AUTOSAR XML (schema 00050)
package /ComponentTypes
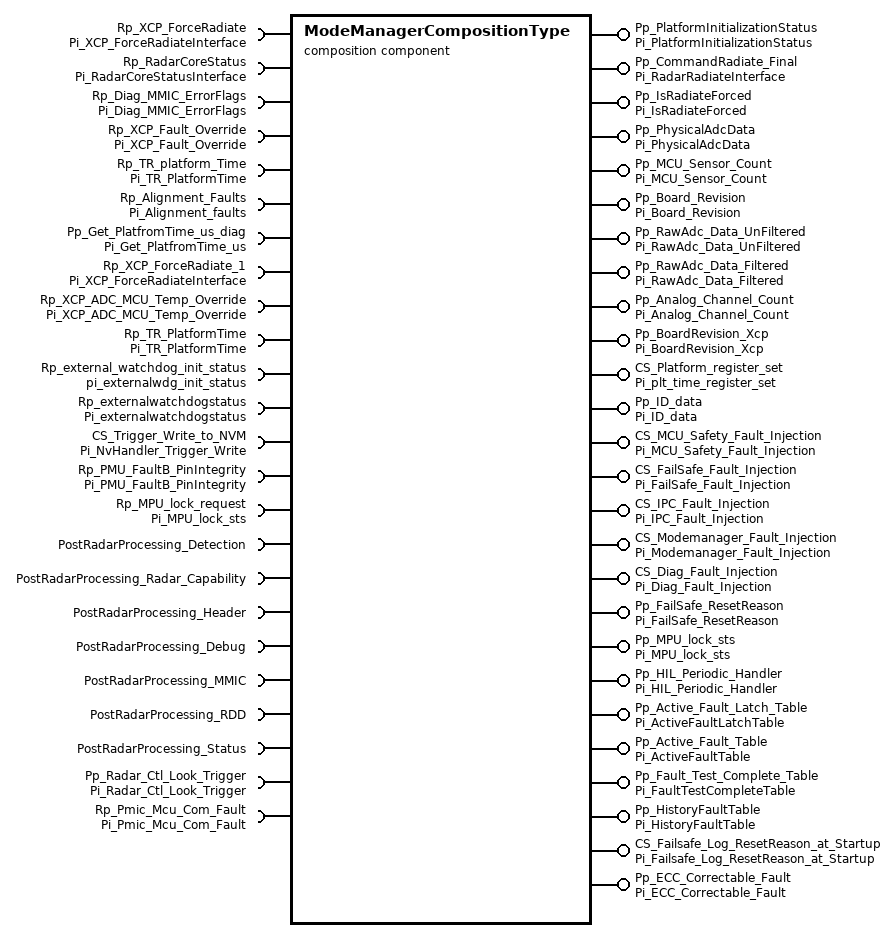
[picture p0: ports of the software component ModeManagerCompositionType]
  composition sw component type ModeManagerCompositionType
    provide port Pp_PlatformInitializationStatus: nonqueued-sender-com-spec{data-element=De_MCU_InitializationStatus, init-value=constant-reference=C_MCU_initlaisation_NOTCompleted_T}, provided-interface=Pi_PlatformInitializationStatus
    require port Rp_XCP_ForceRadiate: nonqueued-receiver-com-spec{data-element=De_XCPForceRadiate, filter=data-filter-type=ALWAYS, init-value=constant-reference=C_Force_Radiate_Init_T}, required-interface=Pi_XCP_ForceRadiateInterface
    provide port Pp_CommandRadiate_Final: nonqueued-sender-com-spec{data-element=De_CommandRadiate_Final, init-value=constant-reference=C_Command_Radiate_Final_T}, provided-interface=Pi_RadarRadiateInterface
    provide port Pp_IsRadiateForced: nonqueued-sender-com-spec{data-element=De_IsRadiateForced, init-value=constant-reference=C_IsRadiateForced_T}, provided-interface=Pi_IsRadiateForced
    8 x require port:
      Rp_RadarCoreStatus: nonqueued-receiver-com-spec{data-element=De_RadarCoreStatus, filter=data-filter-type=ALWAYS, init-value=constant-reference=C_RadarCoreStatus_T}, required-interface=Pi_RadarCoreStatusInterface
      Rp_Diag_MMIC_ErrorFlags: nonqueued-receiver-com-spec{data-element=De_MMIC_ErrorFlags, filter=data-filter-type=ALWAYS, init-value=constant-reference=C_MMIC_ErrorFlags}, required-interface=Pi_Diag_MMIC_ErrorFlags
      Rp_XCP_Fault_Override: nonqueued-receiver-com-spec{data-element=De_XCP_Fault_Override, filter=data-filter-type=ALWAYS, init-value=constant-reference=C_XCP_Fault_Override}, required-interface=Pi_XCP_Fault_Override
      Rp_TR_platform_Time: nonqueued-receiver-com-spec{data-element=De_PlatformTime, filter=data-filter-type=ALWAYS, init-value=85}, required-interface=Pi_TR_PlatformTime
      Rp_Alignment_Faults: nonqueued-receiver-com-spec{data-element=De_Alignment_Faults, filter=data-filter-type=ALWAYS, init-value=constant-reference=C_Alignment_faults}, required-interface=Pi_Alignment_faults
      Pp_Get_PlatfromTime_us_diag: client-com-spec=read, required-interface=Pi_Get_PlatfromTime_us
      Rp_XCP_ForceRadiate_1: nonqueued-receiver-com-spec{data-element=De_XCPForceRadiate, filter=data-filter-type=ALWAYS, init-value=constant-reference=C_Force_Radiate_Init_T}, required-interface=Pi_XCP_ForceRadiateInterface
      Rp_XCP_ADC_MCU_Temp_Override: nonqueued-receiver-com-spec{data-element=De_XCP_ADC_MCU_Temp_Override, filter=data-filter-type=ALWAYS, init-value=1}, required-interface=Pi_XCP_ADC_MCU_Temp_Override
    10 x provide port:
      Pp_PhysicalAdcData: nonqueued-sender-com-spec{data-element=De_PhysicalAdcData, init-value=constant-reference=C_AdcData_T}, provided-interface=Pi_PhysicalAdcData
      Pp_MCU_Sensor_Count: nonqueued-sender-com-spec{data-element=De_MCU_Sensor_Count, init-value=0}, provided-interface=Pi_MCU_Sensor_Count
      Pp_Board_Revision: nonqueued-sender-com-spec{data-element=De_Board_Revision, init-value=85}, provided-interface=Pi_Board_Revision
      Pp_RawAdc_Data_UnFiltered: nonqueued-sender-com-spec{data-element=RawAdcDataUnfiltered, init-value=constant-reference=C_RawAdcData_T}, provided-interface=Pi_RawAdc_Data_UnFiltered
      Pp_RawAdc_Data_Filtered: nonqueued-sender-com-spec{data-element=De_RawAdcData, init-value=constant-reference=C_RawAdcDataFilt_T}, provided-interface=Pi_RawAdc_Data_Filtered
      Pp_Analog_Channel_Count: nonqueued-sender-com-spec{data-element=De_Analog_Channel_Count, init-value=0}, provided-interface=Pi_Analog_Channel_Count
      Pp_BoardRevision_Xcp: nonqueued-sender-com-spec{data-element=De_BoardRevision_Xcp, init-value=0}, provided-interface=Pi_BoardRevision_Xcp
      CS_Platform_register_set: server-com-spec{operation=fault_type, queue-length=1}, provided-interface=Pi_plt_time_register_set
      Pp_ID_data: nonqueued-sender-com-spec{data-element=De_ID_data, init-value=constant-reference=C_ID_data}, provided-interface=Pi_ID_data
      CS_MCU_Safety_Fault_Injection: server-com-spec{operation=Read, queue-length=1}, provided-interface=Pi_MCU_Safety_Fault_Injection
    require port Rp_TR_PlatformTime: nonqueued-receiver-com-spec{data-element=De_PlatformTime, filter=data-filter-type=ALWAYS, init-value=85}, required-interface=Pi_TR_PlatformTime
    provide port CS_FailSafe_Fault_Injection: server-com-spec{operation=Read, queue-length=1}, provided-interface=Pi_FailSafe_Fault_Injection
    provide port CS_IPC_Fault_Injection: server-com-spec{operation=Read, queue-length=1}, provided-interface=Pi_IPC_Fault_Injection
    require port Rp_external_watchdog_init_status: nonqueued-receiver-com-spec{data-element=de_wdginit_status, filter=data-filter-type=ALWAYS, init-value=0}, required-interface=pi_externalwdg_init_status
    require port Rp_externalwatchdogstatus: nonqueued-receiver-com-spec{data-element=de_externalwatchdogstatus, filter=data-filter-type=ALWAYS, init-value=0}, required-interface=Pi_externalwatchdogstatus
    provide port CS_Modemanager_Fault_Injection: server-com-spec{operation=Read, queue-length=1}, provided-interface=Pi_Modemanager_Fault_Injection
    provide port CS_Diag_Fault_Injection: server-com-spec{operation=Read, queue-length=1}, provided-interface=Pi_Diag_Fault_Injection
    provide port Pp_FailSafe_ResetReason: nonqueued-sender-com-spec{data-element=De_FailSafe_ResetReason, init-value=constant-reference=C_FailSafe_ResetReason_T}, provided-interface=Pi_FailSafe_ResetReason
    require port CS_Trigger_Write_to_NVM: client-com-spec=NvHandler_Trigger_Write_To_NVM, required-interface=Pi_NvHandler_Trigger_Write
    require port Rp_PMU_FaultB_PinIntegrity: nonqueued-receiver-com-spec{data-element=De_PMU_FaultB_PinIntegrityStat, filter=data-filter-type=ALWAYS, init-value=0}, required-interface=Pi_PMU_FaultB_PinIntegrity
    provide port Pp_MPU_lock_sts: nonqueued-sender-com-spec{data-element=De_MPU_lock_sts, init-value=0}, provided-interface=Pi_MPU_lock_sts
    require port Rp_MPU_lock_request: nonqueued-receiver-com-spec{data-element=De_MPU_lock_sts, filter=data-filter-type=ALWAYS, init-value=0}, required-interface=Pi_MPU_lock_sts
    6 x provide port:
      Pp_HIL_Periodic_Handler: provided-interface=Pi_HIL_Periodic_Handler
      Pp_Active_Fault_Latch_Table: nonqueued-sender-com-spec{data-element=De_ActiveFaultLatchTable, init-value=constant-reference=C_Fault_T}, provided-interface=Pi_ActiveFaultLatchTable
      Pp_Active_Fault_Table: nonqueued-sender-com-spec{data-element=De_ActiveFaultTable, init-value=constant-reference=C_Fault_T}, provided-interface=Pi_ActiveFaultTable
      Pp_Fault_Test_Complete_Table: nonqueued-sender-com-spec{data-element=De_FaultTestCompleteTable, init-value=constant-reference=C_Fault_T}, provided-interface=Pi_FaultTestCompleteTable
      Pp_HistoryFaultTable: nonqueued-sender-com-spec{data-element=De_HistoryFaultTable, init-value=constant-reference=C_Fault_T}, provided-interface=Pi_HistoryFaultTable
      CS_Failsafe_Log_ResetReason_at_Startup: provided-interface=Pi_Failsafe_Log_ResetReason_at_Startup
    8 x require port:
      PostRadarProcessing_Detection: client-com-spec=Populate_Detection_Stream, required-interface=PostRadarProcessing_Detection
      PostRadarProcessing_Radar_Capability: client-com-spec=Populate_Radar_Capability_Stream, required-interface=PostRadarProcessing_Radar_Capability
      PostRadarProcessing_Header: client-com-spec=Populate_Header_Stream, required-interface=PostRadarProcessing_Header
      PostRadarProcessing_Debug: client-com-spec=Populate_Debug_Stream, required-interface=PostRadarProcessing_Debug
      PostRadarProcessing_MMIC: client-com-spec=Populate_MMIC_Stream, required-interface=PostRadarProcessing_MMIC
      PostRadarProcessing_RDD: client-com-spec=Populate_RDD_Stream, required-interface=PostRadarProcessing_RDD
      PostRadarProcessing_Status: client-com-spec=Populate_Status_Stream, required-interface=PostRadarProcessing_Status
      Pp_Radar_Ctl_Look_Trigger: client-com-spec=Operation, required-interface=Pi_Radar_Ctl_Look_Trigger
    provide port Pp_ECC_Correctable_Fault: nonqueued-sender-com-spec{data-element=De_ECC_Correctable_Fault, init-value=fields=[aa_mem_sec:0, artie_mem_sec:0, csi2_sec:0, dsp_opif_sec:0, dsp_idma_sec:0, dsp_iram_sec_axis:0, dsp_dcache_sec:0, dsp_dram_sec:0, dsp_icache_sec:0, dsp_iram_sec:0, ra_cqmem_sec:0, ra_dpmem_sec:0, ra_estmem_sec:0, ra_idxmem_sec:0, ra_phmem_sec:0, ra_wcmem_sec:0, sp_axi_m_corr:0, sp_axi_s_corr:0, sysmem0_sec:0, sysmem1_sec:0, not_recorded:0]}, provided-interface=Pi_ECC_Correctable_Fault
    require port Rp_Pmic_Mcu_Com_Fault: nonqueued-receiver-com-spec{data-element=De_Pmic_Mcu_Com_Fault, filter=data-filter-type=ALWAYS, init-value=0}, required-interface=Pi_Pmic_Mcu_Com_Fault
    7 x component:
      SWC_CDD_IPC: type=SWC_CDD_IPC
      SWC_PLT_Appl_Diag: type=SWC_PLT_Appl_Diag
      SWC_PLT_Appl_FaultMgr: type=SWC_PLT_Appl_FaultMgr
      SWC_PLT_Appl_IoHwAb: type=SWC_PLT_Appl_IoHwAb
      SWC_PLT_Appl_ModeManager: type=SWC_PLT_Appl_ModeManager
      SWC_PLT_CDD_FailSafe: type=SWC_PLT_CDD_FailSafe
      SWC_PLT_CDD_MCU_Safety: type=SWC_PLT_CDD_MCU_Safety
    connect SWC_PLT_Appl_Diag.Pp_DTC_Status -> SWC_PLT_Appl_FaultMgr.Rp_DTC_Status
    connect SWC_PLT_Appl_Diag.Pp_MCU_Startup_Fault_Status -> SWC_PLT_Appl_FaultMgr.Rp_MCU_Startup_Fault_Status
    connect SWC_PLT_Appl_Diag.Pp_MicroTemp_Low_Deb_Reset -> SWC_PLT_Appl_FaultMgr.Rp_MicroTemp_Low_Deb_Reset
    connect SWC_PLT_Appl_Diag.Pp_Platform_Battery_Tst -> SWC_PLT_Appl_FaultMgr.Rp_Platform_Battery_Tst
    connect SWC_PLT_Appl_Diag.Pp_PltToFltMgr_Can_Bus_Off_Fault_Status -> SWC_PLT_Appl_FaultMgr.Rp_PltToFltMgr_Can_Bus_Off_Fault_Status
    connect SWC_PLT_Appl_Diag.Pp_PltToFltMgr_Can_Controller_Fault_Status -> SWC_PLT_Appl_FaultMgr.Rp_PltToFltMgr_Can_Controller_Fault_Status
    connect SWC_PLT_Appl_Diag.Pp_PltToFltMgr_Host_Micro_Diag -> SWC_PLT_Appl_FaultMgr.Rp_PltToFltMgr_Host_Micro_Diag
    connect SWC_PLT_Appl_Diag.Pp_PltToFltMgr_Micro_Temp_Fault_Status -> SWC_PLT_Appl_FaultMgr.Rp_PltToFltMgr_Micro_Temp_Fault_Status
    connect SWC_PLT_Appl_Diag.Pp_PltToFltMgr_Mirror_Ram_Int_Flt_Sts -> SWC_PLT_Appl_FaultMgr.Rp_PltToFltMgr_Mirror_Ram_Int_Flt_Sts
    connect SWC_PLT_Appl_Diag.Pp_PltToFltMgr_MMIC_A_MMIC_Diag -> SWC_PLT_Appl_FaultMgr.Rp_PltToFltMgr_MMIC_A_MMIC_Diag
    connect SWC_PLT_Appl_Diag.Pp_PltToFltMgr_MMIC_B_Diag -> SWC_PLT_Appl_FaultMgr.Rp_PltToFltMgr_MMIC_B_Diag
    connect SWC_PLT_Appl_Diag.Pp_Radar_Blockage_Flt_Sts -> SWC_PLT_Appl_FaultMgr.Rp_Radar_Blockage_Flt_Sts
    connect SWC_PLT_Appl_Diag.Pp_Radar_Interference_Flt_Sts -> SWC_PLT_Appl_FaultMgr.Rp_Radar_Interference_Flt_Sts
    connect SWC_PLT_Appl_Diag.Pp_Rdr_Hw_Tst -> SWC_PLT_Appl_FaultMgr.Rp_Rdr_Hw_Tst
    connect SWC_PLT_Appl_FaultMgr.Pp_RadarDiagRequestInterface -> SWC_PLT_Appl_ModeManager.Rp_RadarDiagRequest
    connect SWC_PLT_Appl_FaultMgr.Pp_ModeManagerTestResultInterface -> SWC_PLT_Appl_ModeManager.Rp_TR_ModeManager
    connect SWC_PLT_Appl_IoHwAb.CS_ThermMonTemp -> SWC_PLT_Appl_Diag.CS_ThermMonTemp
    connect SWC_PLT_Appl_ModeManager.Pp_OperationMode_System -> SWC_PLT_Appl_Diag.Rp_Operation_Mode_System
    connect SWC_PLT_CDD_MCU_Safety.Pp_PlatformInitializationStatus -> SWC_PLT_Appl_Diag.Rp_PlatformInitializationStatus
    connect SWC_PLT_CDD_MCU_Safety.Pp_TR_initMCU_Fail -> SWC_PLT_Appl_Diag.Rp_TR_initMCU_Fail
    connect SWC_PLT_CDD_MCU_Safety.Pp_PlatformInitializationStatus -> SWC_PLT_Appl_ModeManager.Rp_InitializationStatus
    delegate SWC_PLT_Appl_ModeManager.Pp_CommandRadiate_Final <-> outer port Pp_CommandRadiate_Final
    delegate SWC_PLT_Appl_ModeManager.Pp_IsRadiateForced <-> outer port Pp_IsRadiateForced
    delegate SWC_PLT_Appl_ModeManager.Rp_RadarCoreStatus <-> outer port Rp_RadarCoreStatus
    delegate SWC_PLT_Appl_Diag.Rp_Diag_MMIC_ErrorFlags <-> outer port Rp_Diag_MMIC_ErrorFlags
    connect SWC_PLT_Appl_Diag.Pp_Alignment_Flt_Sts -> SWC_PLT_Appl_FaultMgr.Rp_Alignment_Flt_Sts
    connect SWC_PLT_Appl_Diag.Pp_IPC_Faults_sts -> SWC_PLT_Appl_FaultMgr.Rp_IPC_Faults_sts
    connect SWC_PLT_Appl_Diag.Pp_PltToFltMgr_InterProcessor_Commn -> SWC_PLT_Appl_FaultMgr.Rp_PltToFltMgr_InterProcessor_Commn
    connect SWC_PLT_Appl_Diag.Pp_PltToFltMgr_Memory_Diagnostics -> SWC_PLT_Appl_FaultMgr.Rp_PltToFltMgr_Memory_Diagnostics
    connect SWC_PLT_Appl_Diag.Pp_RFE_Repetitive_Fault_Status -> SWC_PLT_Appl_FaultMgr.Rp_RFE_Repetitive_Fault_Status
    connect SWC_PLT_Appl_Diag.Pp_TR_PlatformTime -> SWC_PLT_Appl_FaultMgr.Rp_TR_PlatformTime
    delegate SWC_PLT_Appl_FaultMgr.Rp_XCP_Fault_Override <-> outer port Rp_XCP_Fault_Override
    connect SWC_PLT_CDD_FailSafe.Pp_Repetitive_Reset_Status -> SWC_PLT_Appl_Diag.Rp_Repetitive_Reset_Status
    connect SWC_PLT_CDD_FailSafe.Pp_RFE_Repetitive_Reset_Status -> SWC_PLT_Appl_Diag.Rp_RFE_Repetitive_Reset_Status
    connect SWC_PLT_CDD_FailSafe.FailSafe_Log_ResetReason -> SWC_PLT_Appl_Diag.FailSafe_Log_ResetReason
    connect SWC_PLT_Appl_IoHwAb.Pp_Vbatt_State -> SWC_PLT_Appl_Diag.Rp_VbattState
    connect SWC_CDD_IPC.Pp_IPC_Faults -> SWC_PLT_Appl_Diag.Rp_IPC_Faults
    connect SWC_CDD_IPC.Pp_RadarCapability_Faults -> SWC_PLT_Appl_Diag.Rp_RadarCapability_Faults
    delegate SWC_PLT_Appl_Diag.Rp_TR_platform_Time <-> outer port Rp_TR_platform_Time
    delegate SWC_PLT_Appl_Diag.Rp_Alignment_Faults <-> outer port Rp_Alignment_Faults
    delegate SWC_PLT_Appl_Diag.Pp_Get_PlatfromTime_us_diag <-> outer port Pp_Get_PlatfromTime_us_diag
    connect SWC_PLT_CDD_MCU_Safety.Pp_ECU_Reset -> SWC_PLT_Appl_ModeManager.Rp_ECU_Reset
    connect SWC_PLT_CDD_MCU_Safety.Pp_Fault_name_For_FHTI_Testing -> SWC_PLT_Appl_ModeManager.Rp_Fault_name_For_FHTI_Testing
    connect SWC_PLT_CDD_FailSafe.Pp_Fault_name_For_FHTI_Testing -> SWC_PLT_Appl_ModeManager.Rp_Fault_name_For_FHTI_Testing
    connect SWC_PLT_CDD_FailSafe.Pp_Repetitive_Reset_Status -> SWC_PLT_Appl_ModeManager.Rp_Repetitive_Reset_Status
    connect SWC_PLT_Appl_IoHwAb.Pp_Vbatt_State -> SWC_PLT_Appl_ModeManager.Rp_Vbattstate
    connect SWC_CDD_IPC.Pp_Fault_name_For_FHTI_Testing -> SWC_PLT_Appl_ModeManager.Rp_Fault_name_For_FHTI_Testing
    delegate SWC_PLT_Appl_ModeManager.Rp_XCP_ForceRadiate <-> outer port Rp_XCP_ForceRadiate_1
    delegate SWC_PLT_Appl_IoHwAb.Rp_XCP_ADC_MCU_Temp_Override <-> outer port Rp_XCP_ADC_MCU_Temp_Override
    delegate SWC_PLT_Appl_IoHwAb.Pp_PhysicalAdcData <-> outer port Pp_PhysicalAdcData
    delegate SWC_PLT_Appl_IoHwAb.Pp_MCU_Sensor_Count <-> outer port Pp_MCU_Sensor_Count
    delegate SWC_PLT_Appl_IoHwAb.Pp_Board_Revision <-> outer port Pp_Board_Revision
    delegate SWC_PLT_Appl_IoHwAb.Pp_RawAdc_Data_UnFiltered <-> outer port Pp_RawAdc_Data_UnFiltered
    delegate SWC_PLT_Appl_IoHwAb.Pp_RawAdc_Data_Filtered <-> outer port Pp_RawAdc_Data_Filtered
    delegate SWC_PLT_Appl_IoHwAb.Pp_Analog_Channel_Count <-> outer port Pp_Analog_Channel_Count
    delegate SWC_PLT_Appl_IoHwAb.Pp_BoardRevision_Xcp <-> outer port Pp_BoardRevision_Xcp
    delegate SWC_PLT_Appl_IoHwAb.CS_Platform_register_set <-> outer port CS_Platform_register_set
    connect SWC_PLT_CDD_FailSafe.Pp_Repetitive_Reset_Status -> SWC_PLT_CDD_MCU_Safety.Rp_Repetitive_Reset_Status
    connect SWC_PLT_CDD_FailSafe.FailSafe_Log_ResetReason -> SWC_PLT_CDD_MCU_Safety.CS_MCU_Safety_FailSafe_ResetReason
    connect SWC_PLT_CDD_MCU_Safety.Pp_MemExceptionInfo -> SWC_PLT_CDD_FailSafe.Rp_MemExceptionInfo
    delegate SWC_PLT_CDD_MCU_Safety.Pp_ID_data <-> outer port Pp_ID_data
    delegate SWC_PLT_CDD_MCU_Safety.CS_MCU_Safety_Fault_Injection <-> outer port CS_MCU_Safety_Fault_Injection
    delegate SWC_PLT_CDD_MCU_Safety.Rp_TR_PlatformTime <-> outer port Rp_TR_PlatformTime
    delegate SWC_PLT_CDD_FailSafe.CS_FailSafe_Fault_Injection <-> outer port CS_FailSafe_Fault_Injection
    delegate SWC_CDD_IPC.CS_IPC_Fault_Injection <-> outer port CS_IPC_Fault_Injection
    delegate SWC_PLT_CDD_MCU_Safety.Rp_external_watchdog_init_status <-> outer port Rp_external_watchdog_init_status
    delegate SWC_PLT_Appl_Diag.Rp_externalwatchdogstatus <-> outer port Rp_externalwatchdogstatus
    delegate SWC_PLT_Appl_ModeManager.CS_Modemanager_Fault_Injection <-> outer port CS_Modemanager_Fault_Injection
    delegate SWC_PLT_Appl_Diag.CS_Diag_Fault_Injection <-> outer port CS_Diag_Fault_Injection
    delegate SWC_PLT_CDD_FailSafe.Pp_FailSafe_ResetReason <-> outer port Pp_FailSafe_ResetReason
    delegate SWC_PLT_CDD_FailSafe.CS_Trigger_Write_to_NVM <-> outer port CS_Trigger_Write_to_NVM
    delegate SWC_PLT_CDD_MCU_Safety.Rp_PMU_FaultB_PinIntegrity <-> outer port Rp_PMU_FaultB_PinIntegrity
    delegate SWC_PLT_CDD_MCU_Safety.Pp_MPU_lock_sts <-> outer port Pp_MPU_lock_sts
    delegate SWC_PLT_CDD_MCU_Safety.Rp_MPU_lock_request <-> outer port Rp_MPU_lock_request
    delegate SWC_CDD_IPC.Pp_HIL_Periodic_Handler <-> outer port Pp_HIL_Periodic_Handler
    delegate SWC_PLT_Appl_FaultMgr.Pp_Active_Fault_Table <-> outer port Pp_Active_Fault_Table
    delegate SWC_PLT_Appl_FaultMgr.Pp_Fault_Test_Complete_Table <-> outer port Pp_Fault_Test_Complete_Table
    delegate SWC_PLT_Appl_FaultMgr.Pp_HistoryFaultTable <-> outer port Pp_HistoryFaultTable
    connect SWC_CDD_IPC.Pp_StaticRegCheckFailureInfo -> SWC_PLT_CDD_MCU_Safety.Rp_StaticRegCheckFailureInfo
    connect SWC_PLT_CDD_MCU_Safety.Pp_StaticRegCheckFailureInfo -> SWC_PLT_CDD_FailSafe.Rp_StaticRegCheckFailureInfo
    connect SWC_PLT_CDD_FailSafe.Pp_Hardware_Fault_Status -> SWC_PLT_Appl_Diag.Rp_Hardware_Fault_Status
    delegate SWC_CDD_IPC.PostRadarProcessing_Detection <-> outer port PostRadarProcessing_Detection
    delegate SWC_CDD_IPC.PostRadarProcessing_Radar_Capability <-> outer port PostRadarProcessing_Radar_Capability
    delegate SWC_CDD_IPC.PostRadarProcessing_Header <-> outer port PostRadarProcessing_Header
    delegate SWC_CDD_IPC.PostRadarProcessing_Debug <-> outer port PostRadarProcessing_Debug
    delegate SWC_CDD_IPC.PostRadarProcessing_MMIC <-> outer port PostRadarProcessing_MMIC
    delegate SWC_CDD_IPC.PostRadarProcessing_RDD <-> outer port PostRadarProcessing_RDD
    delegate SWC_CDD_IPC.PostRadarProcessing_Status <-> outer port PostRadarProcessing_Status
    delegate SWC_CDD_IPC.Pp_Radar_Ctl_Look_Trigger <-> outer port Pp_Radar_Ctl_Look_Trigger
    delegate SWC_PLT_CDD_FailSafe.Pp_ECC_Correctable_Fault <-> outer port Pp_ECC_Correctable_Fault
    delegate SWC_PLT_Appl_Diag.Rp_Pmic_Mcu_Com_Fault <-> outer port Rp_Pmic_Mcu_Com_Fault
